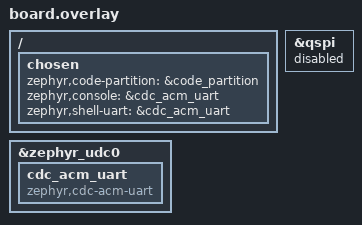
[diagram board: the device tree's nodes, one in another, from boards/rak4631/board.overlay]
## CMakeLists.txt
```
# SPDX-License-Identifier: MIT
# ZephCore Flash Formatter — erases all filesystem partitions, reboots to UF2 DFU.
#
# Build:  west build -b rak4631/nrf52840 zephcore/tools/formatter --pristine
# Flash:  drag-drop build/zephyr/zephyr.uf2 onto UF2 drive

cmake_minimum_required(VERSION 3.20.0)

# Reuse the main project's custom board definitions (overlays for partitions)
list(APPEND BOARD_ROOT ${CMAKE_CURRENT_SOURCE_DIR}/../..)

# Extract base board name (strip qualifier like /nrf52840)
string(REPLACE "/" ";" BOARD_PARTS ${BOARD})
list(GET BOARD_PARTS 0 BOARD_BASE)

# Find board.overlay — prefer formatter-specific overlay (minimal, no sensors/GPS),
# fall back to main board overlay (full hardware definitions).
# Formatter overlays live in tools/formatter/boards/<board>/board.overlay
file(GLOB_RECURSE FMT_OVERLAY_CANDIDATES
     "${CMAKE_CURRENT_SOURCE_DIR}/boards/*/${BOARD_BASE}/board.overlay"
     "${CMAKE_CURRENT_SOURCE_DIR}/boards/${BOARD_BASE}/board.overlay")
if(FMT_OVERLAY_CANDIDATES)
    list(GET FMT_OVERLAY_CANDIDATES 0 FORMATTER_BOARD_OVERLAY)
else()
    # Fall back to main board overlay (partitions + full hardware)
    file(GLOB_RECURSE BOARD_OVERLAY_CANDIDATES
         "${CMAKE_CURRENT_SOURCE_DIR}/../../boards/*/${BOARD_BASE}/board.overlay")
    if(BOARD_OVERLAY_CANDIDATES)
        list(GET BOARD_OVERLAY_CANDIDATES 0 FORMATTER_BOARD_OVERLAY)
    endif()
endif()
if(FORMATTER_BOARD_OVERLAY)
    if(EXTRA_DTC_OVERLAY_FILE)
        set(EXTRA_DTC_OVERLAY_FILE "${EXTRA_DTC_OVERLAY_FILE};${FORMATTER_BOARD_OVERLAY}" CACHE STRING "" FORCE)
    else()
        set(EXTRA_DTC_OVERLAY_FILE "${FORMATTER_BOARD_OVERLAY}" CACHE STRING "" FORCE)
    endif()
endif()

# Find formatter-specific board.conf (e.g., QSPI enablement)
# These live in tools/formatter/boards/<board_base>/board.conf
file(GLOB_RECURSE FMT_BOARD_CONF_CANDIDATES
     "${CMAKE_CURRENT_SOURCE_DIR}/boards/*/${BOARD_BASE}/board.conf"
     "${CMAKE_CURRENT_SOURCE_DIR}/boards/${BOARD_BASE}/board.conf")
if(FMT_BOARD_CONF_CANDIDATES)
    list(GET FMT_BOARD_CONF_CANDIDATES 0 FMT_BOARD_CONF)
    if(EXTRA_CONF_FILE)
        set(EXTRA_CONF_FILE "${EXTRA_CONF_FILE};${FMT_BOARD_CONF}" CACHE STRING "" FORCE)
    else()
        set(EXTRA_CONF_FILE "${FMT_BOARD_CONF}" CACHE STRING "" FORCE)
    endif()
endif()

message(STATUS "Formatter board overlay: ${FORMATTER_BOARD_OVERLAY}")
message(STATUS "Formatter board conf: ${FMT_BOARD_CONF}")

# Read the SoftDevice firmware ID from the MAIN board.conf for this board.
# The Adafruit bootloader rejects a DFU package whose --sd-req doesn't match the
# SoftDevice it's running, which is exactly the guard we want: the SDv6 formatter
# must never apply to an SDv7 node (wrong partition map = corrupted node).
#   SoftDevice v6 -> 0x00B6      SoftDevice v7 -> 0x0123
file(GLOB_RECURSE MAIN_BOARD_CONF_CANDIDATES
     "${CMAKE_CURRENT_SOURCE_DIR}/../../boards/*/${BOARD_BASE}/board.conf")
if(MAIN_BOARD_CONF_CANDIDATES)
    list(GET MAIN_BOARD_CONF_CANDIDATES 0 MAIN_BOARD_CONF)
    file(STRINGS "${MAIN_BOARD_CONF}" _sd_fwid_line REGEX "^CONFIG_ZEPHCORE_SD_FWID=")
    if(_sd_fwid_line)
        string(REGEX REPLACE "^CONFIG_ZEPHCORE_SD_FWID=" "" FORMATTER_SD_REQ "${_sd_fwid_line}")
    endif()
endif()

find_package(Zephyr REQUIRED HINTS $ENV{ZEPHYR_BASE})
project(zephcore_formatter)

target_sources(app PRIVATE src/main.c src/qspi_probe.c)

# Generate an Adafruit DFU package (.zip) next to the .uf2. The .zip is what the
# Mesh America configurator uses for its automated `erase` flow (spec §4a); the
# .uf2 remains the manual drag-and-drop fallback. See PROVIDER_CATALOG.md.
find_program(ADAFRUIT_NRFUTIL adafruit-nrfutil)
if(ADAFRUIT_NRFUTIL AND FORMATTER_SD_REQ)
  add_custom_target(dfu_zip ALL
    COMMAND ${ADAFRUIT_NRFUTIL} dfu genpkg
      --dev-type 0x0052
      --sd-req ${FORMATTER_SD_REQ}
      --application ${CMAKE_BINARY_DIR}/zephyr/zephyr.hex
      ${CMAKE_BINARY_DIR}/zephyr/zephyr.zip
    DEPENDS ${CMAKE_BINARY_DIR}/zephyr/zephyr.hex
    COMMENT "Generating formatter DFU package: zephyr.zip (sd-req=${FORMATTER_SD_REQ})"
    VERBATIM
  )
  add_dependencies(dfu_zip zephyr_final)
  message(STATUS "Formatter DFU zip: ENABLED (sd-req=${FORMATTER_SD_REQ})")
else()
  message(STATUS "Formatter DFU zip: DISABLED (adafruit-nrfutil or SD_FWID missing)")
endif()
```

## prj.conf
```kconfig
# ZephCore Universal Flash Formatter — minimal config
# QSPI erase uses bare-metal register probing (qspi_probe.c) — no driver needed

# Flash access
CONFIG_FLASH=y
CONFIG_FLASH_MAP=y

# Use DTS code_partition for linker origin (required for bootloader boards)
CONFIG_USE_DT_CODE_PARTITION=y

# UF2 output
CONFIG_BUILD_OUTPUT_UF2=y

# USB CDC console (new stack — must match main app)
CONFIG_USB_DEVICE_STACK_NEXT=y
CONFIG_SERIAL=y
CONFIG_CONSOLE=y
CONFIG_UART_CONSOLE=y
CONFIG_UART_LINE_CTRL=y
CONFIG_CDC_ACM_SERIAL_INITIALIZE_AT_BOOT=y
CONFIG_CDC_ACM_SERIAL_ENABLE_AT_BOOT=y

# No logging, no BLE, no LoRa — just erase and reboot
CONFIG_LOG=n
CONFIG_ASSERT=n

# GPIO for LED feedback
CONFIG_GPIO=y

# Reboot API
CONFIG_REBOOT=y

# Don't mount filesystems — we're erasing them
CONFIG_FILE_SYSTEM=n

# Disable peripherals auto-enabled by board overlay DTS nodes.
# Without this, GNSS/I2C/sensor drivers init and hang on boards
# where GPS or sensors aren't physically connected.
CONFIG_GNSS=n
CONFIG_I2C=n
CONFIG_SENSOR=n
CONFIG_SPI=n
```

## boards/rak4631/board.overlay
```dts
/*
 * RAK4631 formatter overlay — flash partitions + USB console only.
 * Strips all sensor/GPS/radio nodes from the main board overlay
 * to avoid driver init hangs in the minimal formatter environment.
 */

/delete-node/ &boot_partition;
/delete-node/ &slot0_partition;
/delete-node/ &slot1_partition;
/delete-node/ &storage_partition;

/ {
	chosen {
		zephyr,code-partition = &code_partition;
		zephyr,console = &cdc_acm_uart;
		zephyr,shell-uart = &cdc_acm_uart;
		/* No zephyr,settings-partition — nRF52 uses file-based settings */
	};
};

&zephyr_udc0 {
	cdc_acm_uart: cdc_acm_uart {
		compatible = "zephyr,cdc-acm-uart";
	};
};

/* Disable QSPI — RAK19003 Mini Base has no QSPI flash */
&qspi {
	status = "disabled";
};

/* Arduino MeshCore compatible partition layout (SoftDevice v6) */
#include "../../../../boards/common/nrf52_partitions_sdv6.dtsi"
```

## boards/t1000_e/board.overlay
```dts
/*
 * T1000-E formatter overlay — USB console only.
 * Strips GPS/sensor nodes from the main board overlay
 * to avoid driver init hangs in the minimal formatter environment.
 *
 * This overlay is used as the SDv7 universal build target.
 * The resulting UF2 works on ALL nRF52840 boards with SoftDevice v7:
 *   T1000-E, Wio Tracker L1, Ikoka Nano 30dBm
 */

/ {
	chosen {
		zephyr,console = &cdc_acm_uart;
		zephyr,shell-uart = &cdc_acm_uart;
	};

	/* Delete GPS control nodes from main board overlay */
	/delete-node/ gps-enable;
	/delete-node/ gps-vrtc-enable;
	/delete-node/ gps-reset;
	/delete-node/ gps-sleep-int;
	/delete-node/ gps-rtc-int;
	/delete-node/ gps-resetb;
};

&zephyr_udc0 {
	cdc_acm_uart: cdc_acm_uart {
		compatible = "zephyr,cdc-acm-uart";
	};
};
```

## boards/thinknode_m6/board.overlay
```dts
/*
 * ThinkNode M6 formatter overlay — minimal drivers.
 *
 * The M6 board DTS no longer carries the QSPI flash: no shipped unit has the
 * chip fitted, so the board dropped &qspi, its partition, the P0.21 enable
 * regulator and the qspi-ext.dtsi (/ext) include together (see the note in
 * thinknode_m6.dts).  There is therefore no /ext LittleFS instance to drop
 * and no QSPI enable to hog here; main.c's PARTITION_EXISTS() checks
 * simply skip the QSPI erase.  If the board ever restores QSPI, restore the
 * "/delete-node/ &qspi_lfs;" and the P0.21 hog that used to live here.
 *
 * Replace the regulator-fixed power-enable node with a gpio-hog so
 * CONFIG_REGULATOR is not forced on by regulator-boot-on.
 */

/* Remove regulator-fixed node and replace with a gpio-hog */
/delete-node/ &pwr_enable;

&gpio0 {
	/* Board power enable (PIN_PWR_EN = P0.27) */
	pwr-en-hog {
		gpio-hog;
		gpios = <27 GPIO_ACTIVE_HIGH>;
		output-high;
		line-name = "PWR Enable";
	};
};
```

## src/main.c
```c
/*
 * ZephCore Universal Flash Formatter
 *
 * Erases all filesystem partitions and reboots into Adafruit UF2 DFU mode
 * for clean firmware installation.
 *
 * Only TWO UF2 binaries are needed for all nRF52840 boards:
 *   - SDv6: covers RAK4631, ThinkNode M1/M3/M6, ProMicro LR2021, RAK WisMesh Tag
 *   - SDv7: covers T1000-E, Wio Tracker L1, Ikoka Nano 30dBm
 *
 * Internal flash uses DTS PARTITION_EXISTS — partition layout is identical
 * across all boards with the same SoftDevice version.
 *
 * QSPI external flash uses bare-metal register probing (qspi_probe.c) — no
 * Zephyr QSPI driver needed. The probe table contains known pin configurations
 * for all QSPI-capable boards; it auto-detects which board is running and
 * erases the external flash if present, or silently skips if not.
 *
 * Build:
 *   SDv6:  west build -b rak4631/nrf52840  zephcore/tools/formatter --pristine
 *   SDv7:  west build -b t1000_e/nrf52840  zephcore/tools/formatter --pristine
 *
 * Flash: drag-drop build/zephyr/zephyr.uf2 onto UF2 drive
 *
 * SPDX-License-Identifier: MIT
 */

#include <zephyr/kernel.h>
#include <zephyr/device.h>
#include <zephyr/drivers/flash.h>
#include <zephyr/drivers/gpio.h>
#include <zephyr/storage/flash_map.h>
#include <zephyr/sys/reboot.h>
#include <errno.h>
#include "qspi_probe.h"

#if defined(CONFIG_SOC_SERIES_NRF52)
#include <hal/nrf_power.h>
#define IS_NRF52 1
#else
#define IS_NRF52 0
#endif

/* Adafruit UF2 bootloader magic — enter mass storage DFU mode */
#define BOOTLOADER_DFU_UF2_MAGIC  0x57

/* ── LED feedback (optional — may not match actual board) ──── */

#if DT_NODE_EXISTS(DT_ALIAS(led0)) && !IS_NRF52
/* Only use DTS LED on non-nRF52 (board-specific builds).
 * On nRF52 universal builds, skip LED to avoid toggling
 * wrong pins on boards other than the build target. */
#define HAS_LED 1
static const struct gpio_dt_spec led = GPIO_DT_SPEC_GET(DT_ALIAS(led0), gpios);
static void led_init(void)  { gpio_pin_configure_dt(&led, GPIO_OUTPUT_ACTIVE); }
static void led_on(void)    { gpio_pin_set_dt(&led, 1); }
static void led_off(void)   { gpio_pin_set_dt(&led, 0); }
#else
#define HAS_LED 0
static void led_init(void)  {}
static void led_on(void)    {}
static void led_off(void)   {}
#endif

/* ── Flash erase helper ──────────────────────────────────────── */

static int erase_partition(uint8_t id, const char *name)
{
	const struct flash_area *fa;
	int rc;

	rc = flash_area_open(id, &fa);
	if (rc) {
		printk("  %s: open failed (rc %d) — skipped\n", name, rc);
		return rc;
	}

	printk("  %s: erasing 0x%lx - 0x%lx (%u KB)...",
	       name,
	       (unsigned long)fa->fa_off,
	       (unsigned long)(fa->fa_off + fa->fa_size),
	       (unsigned)(fa->fa_size / 1024));

	rc = flash_area_erase(fa, 0, fa->fa_size);
	if (rc) {
		printk(" FAILED (rc %d)\n", rc);
	} else {
		printk(" OK\n");
	}

	flash_area_close(fa);
	return rc;
}

/* ── Main ────────────────────────────────────────────────────── */

int main(void)
{
	int errors = 0;

	/* Brief delay for USB CDC to enumerate */
	k_msleep(2000);

	printk("\n");
	printk("=== ZephCore Flash Formatter ===\n");
	printk("\n");

	led_init();
	led_on();

	/* ── LittleFS partition (all platforms) ── */
#if PARTITION_EXISTS(lfs_partition)
	if (erase_partition(PARTITION_ID(lfs_partition), "LittleFS (/lfs)")) {
		errors++;
	}
#endif

	/* ── NVS storage partition (ESP32 etc.) ── */
#if PARTITION_EXISTS(storage_partition)
	if (erase_partition(PARTITION_ID(storage_partition), "NVS (storage)")) {
		errors++;
	}
#endif

	/* ── QSPI external flash (auto-detect via pin probing) ── */
	/* Probes all known boards. Finding no flash is normal (most boards have
	 * none); a flash that answered and then failed to erase is an error. */
	int qspi_rc = qspi_probe_and_erase();

	if (qspi_rc && qspi_rc != -ENODEV) {
		errors++;
	}

	led_off();

	/* ── Summary ── */
	printk("\n");
	if (errors) {
		printk("Completed with %d error(s).\n", errors);
	} else if (qspi_rc == 0) {
		printk("All partitions erased successfully (internal flash + QSPI).\n");
	} else {
		printk("Internal flash erased successfully. No external QSPI flash was\n");
		printk("erased: none answered (normal on a board without one).\n");
	}

	printk("Rebooting into UF2 DFU mode...\n");
	printk("You can now drag-drop your new firmware UF2.\n");
	k_msleep(500);

	/* ── Reboot to UF2 bootloader ── */
#if IS_NRF52
	nrf_power_gpregret_set(NRF_POWER, 0, BOOTLOADER_DFU_UF2_MAGIC);
#endif
	sys_reboot(SYS_REBOOT_COLD);

	return 0; /* never reached */
}
```

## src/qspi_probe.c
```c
/*
 * SPDX-License-Identifier: MIT
 * Universal QSPI flash probe and erase — bare-metal nRF52840 register access
 *
 * Bypasses the Zephyr QSPI driver entirely. Directly configures the nRF52840
 * QSPI peripheral's PSEL (pin select) registers, sends standard JEDEC SPI NOR
 * commands via the custom instruction interface (CINSTR), and performs a full
 * chip erase when a flash chip responds.
 *
 * To add a new board: append an entry to known_boards[] with its QSPI pin
 * mapping and optional power-enable GPIO. No DTS or Kconfig changes needed.
 */

#include <zephyr/kernel.h>
#include <zephyr/devicetree.h>
#include <errno.h>
#include "qspi_probe.h"

#if defined(CONFIG_SOC_NRF52840)

#include <nrfx.h>
#include <hal/nrf_gpio.h>

/* ── SPI NOR flash commands (JEDEC standard — all chips) ──── */

#define CMD_READ_ID      0x9F  /* Read JEDEC ID: manufacturer + type + capacity */
#define CMD_WRITE_EN     0x06  /* Write Enable (required before erase) */
#define CMD_CHIP_ERASE   0xC7  /* Full chip erase */
#define CMD_READ_STATUS  0x05  /* Read Status Register 1 */
#define CMD_RELEASE_DPD  0xAB  /* Release from Deep Power-Down */
#define CMD_READ         0x03  /* Read data, 24-bit address */
#define STATUS_WIP       0x01  /* Write-In-Progress bit in status register */

/* ── CINSTRCONF length values (opcode + N-1 data bytes) ───── */

#define CINSTR_1B   1  /* opcode only */
#define CINSTR_2B   2  /* opcode + 1 byte response */
#define CINSTR_4B   4  /* opcode + 3 bytes response (JEDEC ID) */
#define CINSTR_8B   8  /* opcode + 3 address bytes + 4 data bytes (READ) */

/* A flash behind a switched rail needs time after the rail comes up before it
 * answers: one settle, then a few more tries (MeshTracker X1 answered 00 00 00
 * right after its rail was switched on). */
#define PWR_SETTLE_MS    100
#define PWR_RETRY_MS     200
#define PWR_RETRIES      2

/* Which SoftDevice this image is built for, from where the application starts
 * (0x26000 under v6, 0x27000 under v7). */
#define SD_ANY  0
#define SD_V6   6
#define SD_V7   7
#define BUILD_SD ((DT_REG_ADDR(DT_CHOSEN(zephyr_code_partition)) == 0x27000) ? SD_V7 : SD_V6)

/* ── Pin encoding: matches nRF52840 PSEL register format ──── */

#define QPIN(port, pin)    (((port) << 5) | (pin))
#define QPIN_NONE          0xFF
#define QPIN_PORT(p)       (((p) >> 5) & 1)
#define QPIN_PIN(p)        ((p) & 0x1F)

/* PSEL register value: pin connected */
#define PSEL_DISCONNECT    (1UL << 31)

/* ── Known board QSPI pin configurations ─────────────────── */

struct qspi_pin_config {
	const char *name;
	uint8_t sck, csn, io0, io1, io2, io3;
	uint8_t pwr_pin;  /* GPIO to drive HIGH before probe, QPIN_NONE if none */
	uint8_t sd;       /* SD_V6/SD_V7: probe only in that build; SD_ANY: both */
};

/*
 * Pin table — add new boards here.
 * Sourced from ZephCore DTS + Arduino MeshCore variants.
 *
 * PWR is the GPIO that switches the flash's supply rail. The firmware raises it
 * from a regulator node; here nothing else does, and the rail has been off for
 * the bootloader's whole DFU, so a missing PWR pin reads as "no flash".
 *
 * Config                     SCK      CSN      IO0      IO1      IO2      IO3      PWR      Flash chip       Boards
 * ───────────────────────── ──────── ──────── ──────── ──────── ──────── ──────── ──────── ──────────────── ────────────────────────────────────────
 * Wio/XIAO/Ikoka/SenseCap   P0.21    P0.25    P0.20    P0.24    P0.22    P0.23    —        P25Q16H 2MB      Wio Tracker L1 (+ Pro 1W), XIAO nRF52, Ikoka Stick/Nano/Handheld, SenseCap Solar
 * ThinkNode M1 / TEcho       P1.14    P1.15    P1.12    P1.13    P0.07    P0.05    P0.12    MX25R1635F 2MB   ThinkNode M1, LilyGo TEcho
 * ThinkNode M6               P1.03    P0.23    P1.01    P1.02    P1.04    P1.05    P0.21    MX25R1635F 2MB   ThinkNode M6
 * RAK4631 / GAT562           P0.03    P0.26    P0.30    P0.29    P0.28    P0.02    —        IS25LP080D 1MB   RAK4631, RAK3401, GAT562 variants
 * LilyGo TEcho Lite          P0.04    P0.12    P0.06    P0.08    P1.09    P0.26    —        ZD25WQ32C 4MB    LilyGo TEcho Lite
 * Nano G2 Ultra              P0.08    P1.07    P0.06    P0.26    P1.04    P1.02    —        W25Q16JV 2MB     Nano G2 Ultra
 * LilyGo T-Impulse Plus      P0.04    P0.12    P0.06    P1.09    P0.08    P0.26    P0.14    ZD25WQ32C 4MB    LilyGo T-Impulse Plus (SD v6; IO1/IO2 are the TEcho Lite's swapped)
 * MeshTracker X1             P0.19    P0.20    P0.21    P0.22    P0.23    P1.00    P0.15    GD25Q64E 8MB     MeshTracker X1 (SD v7)
 */
static const struct qspi_pin_config known_boards[] = {
	{
		.name = "Wio/XIAO/Ikoka/SenseCap",
		.sck = QPIN(0, 21), .csn = QPIN(0, 25),
		.io0 = QPIN(0, 20), .io1 = QPIN(0, 24),
		.io2 = QPIN(0, 22), .io3 = QPIN(0, 23),
		.pwr_pin = QPIN_NONE,
	},
	{
		.name = "ThinkNode M1 / TEcho",
		.sck = QPIN(1, 14), .csn = QPIN(1, 15),
		.io0 = QPIN(1, 12), .io1 = QPIN(1, 13),
		.io2 = QPIN(0,  7), .io3 = QPIN(0,  5),
		.pwr_pin = QPIN(0, 12),
	},
	{
		.name = "ThinkNode M6",
		.sck = QPIN(1,  3), .csn = QPIN(0, 23),
		.io0 = QPIN(1,  1), .io1 = QPIN(1,  2),
		.io2 = QPIN(1,  4), .io3 = QPIN(1,  5),
		.pwr_pin = QPIN(0, 21),
	},
	{
		.name = "RAK4631 / GAT562",
		.sck = QPIN(0,  3), .csn = QPIN(0, 26),
		.io0 = QPIN(0, 30), .io1 = QPIN(0, 29),
		.io2 = QPIN(0, 28), .io3 = QPIN(0,  2),
		.pwr_pin = QPIN_NONE,
	},
	{
		.name = "LilyGo TEcho Lite",
		.sck = QPIN(0,  4), .csn = QPIN(0, 12),
		.io0 = QPIN(0,  6), .io1 = QPIN(0,  8),
		.io2 = QPIN(1,  9), .io3 = QPIN(0, 26),
		.pwr_pin = QPIN_NONE,
	},
	{
		.name = "Nano G2 Ultra",
		.sck = QPIN(0,  8), .csn = QPIN(1,  7),
		.io0 = QPIN(0,  6), .io1 = QPIN(0, 26),
		.io2 = QPIN(1,  4), .io3 = QPIN(1,  2),
		.pwr_pin = QPIN_NONE,
	},
	{
		.name = "LilyGo T-Impulse Plus",
		.sck = QPIN(0,  4), .csn = QPIN(0, 12),
		.io0 = QPIN(0,  6), .io1 = QPIN(1,  9),
		.io2 = QPIN(0,  8), .io3 = QPIN(0, 26),
		.pwr_pin = QPIN(0, 14),
		.sd = SD_V6,
	},
	{
		.name = "MeshTracker X1",
		.sck = QPIN(0, 19), .csn = QPIN(0, 20),
		.io0 = QPIN(0, 21), .io1 = QPIN(0, 22),
		.io2 = QPIN(0, 23), .io3 = QPIN(1,  0),
		.pwr_pin = QPIN(0, 15),
		.sd = SD_V7,
	},
};

/* ── GPIO helpers (raw register access) ───────────────────── */

static NRF_GPIO_Type *gpio_port_reg(uint8_t qpin)
{
	return QPIN_PORT(qpin) ? NRF_P1 : NRF_P0;
}

static void gpio_set_output_high(uint8_t qpin)
{
	NRF_GPIO_Type *port = gpio_port_reg(qpin);
	uint8_t pin = QPIN_PIN(qpin);

	nrf_gpio_cfg_output(qpin);
	port->OUTSET = (1UL << pin);
}

static void gpio_release(uint8_t qpin)
{
	NRF_GPIO_Type *port = gpio_port_reg(qpin);
	uint8_t pin = QPIN_PIN(qpin);

	port->OUTCLR = (1UL << pin);
	nrf_gpio_cfg_default(qpin);
}

/* ── QSPI register helpers ────────────────────────────────── */

static void qspi_disconnect_pins(void)
{
	NRF_QSPI->PSEL.SCK = PSEL_DISCONNECT;
	NRF_QSPI->PSEL.CSN = PSEL_DISCONNECT;
	NRF_QSPI->PSEL.IO0 = PSEL_DISCONNECT;
	NRF_QSPI->PSEL.IO1 = PSEL_DISCONNECT;
	NRF_QSPI->PSEL.IO2 = PSEL_DISCONNECT;
	NRF_QSPI->PSEL.IO3 = PSEL_DISCONNECT;
}

static void qspi_set_pins(const struct qspi_pin_config *cfg)
{
	NRF_QSPI->PSEL.SCK = cfg->sck;
	NRF_QSPI->PSEL.CSN = cfg->csn;
	NRF_QSPI->PSEL.IO0 = cfg->io0;
	NRF_QSPI->PSEL.IO1 = cfg->io1;
	NRF_QSPI->PSEL.IO2 = cfg->io2;
	NRF_QSPI->PSEL.IO3 = cfg->io3;
}

static bool qspi_wait_ready(int timeout_ms)
{
	int64_t deadline = k_uptime_get() + timeout_ms;

	while (!NRF_QSPI->EVENTS_READY) {
		if (k_uptime_get() > deadline) {
			return false;
		}
		k_msleep(1);
	}
	NRF_QSPI->EVENTS_READY = 0;
	return true;
}

static bool qspi_activate(void)
{
	/* Single-bit SPI mode, 24-bit addressing, no DPM */
	NRF_QSPI->IFCONFIG0 = 0;

	/* 2 MHz (SCKFREQ=15 → 32MHz/16), 8µs CSN delay, SPI mode 0 */
	NRF_QSPI->IFCONFIG1 = (15UL << 28) | 128;

	NRF_QSPI->ENABLE = QSPI_ENABLE_ENABLE_Enabled;
	NRF_QSPI->EVENTS_READY = 0;
	NRF_QSPI->TASKS_ACTIVATE = 1;

	return qspi_wait_ready(500);
}

static void qspi_deactivate(void)
{
	NRF_QSPI->EVENTS_READY = 0;
	NRF_QSPI->TASKS_DEACTIVATE = 1;
	qspi_wait_ready(500);
	NRF_QSPI->ENABLE = QSPI_ENABLE_ENABLE_Disabled;
	qspi_disconnect_pins();
}

/**
 * Execute a custom instruction via CINSTR interface.
 * @param opcode  SPI NOR command opcode
 * @param len     Total bytes (opcode + response), 1-9
 * @param dat0    Output: CINSTRDAT0 register value (response bytes), or NULL
 * @return true on success, false on timeout
 */
static bool qspi_cinstr(uint8_t opcode, uint8_t len, uint32_t *dat0)
{
	NRF_QSPI->CINSTRDAT0 = 0;
	NRF_QSPI->EVENTS_READY = 0;
	NRF_QSPI->CINSTRCONF = ((uint32_t)opcode) |
				((uint32_t)len << 8) |
				(1UL << 12) |  /* LIO2: hold IO2 HIGH (not used in single-bit) */
				(1UL << 13);   /* LIO3: hold IO3 HIGH (not used in single-bit) */

	if (!qspi_wait_ready(500)) {
		return false;
	}

	if (dat0) {
		*dat0 = NRF_QSPI->CINSTRDAT0;
	}
	return true;
}

/**
 * Read the 4 bytes at flash address 0 (READ 0x03, single-line).
 * The address goes out from CINSTRDAT0 bytes 0-2; the data comes back in the
 * byte slots after it: CINSTRDAT0 byte 3 and CINSTRDAT1 bytes 0-2.
 */
static bool qspi_read_first4(uint32_t *out)
{
	NRF_QSPI->CINSTRDAT0 = 0;
	NRF_QSPI->CINSTRDAT1 = 0;
	NRF_QSPI->EVENTS_READY = 0;
	NRF_QSPI->CINSTRCONF = ((uint32_t)CMD_READ) |
				((uint32_t)CINSTR_8B << 8) |
				(1UL << 12) | (1UL << 13);

	if (!qspi_wait_ready(500)) {
		return false;
	}

	*out = (NRF_QSPI->CINSTRDAT0 >> 24) | (NRF_QSPI->CINSTRDAT1 << 8);
	return true;
}

/* ── Per-config probe and erase ───────────────────────────── */

/* @return 0 erased, -ENODEV nothing answered on these pins, -EIO a flash
 * answered but the erase failed.
 */
static int probe_one(const struct qspi_pin_config *cfg)
{
	uint32_t dat0, first4;
	uint8_t mfr, type, cap;
	int rc = -ENODEV;

	printk("  Probing %s pins...", cfg->name);

	/* Power-enable GPIO if needed */
	if (cfg->pwr_pin != QPIN_NONE) {
		gpio_set_output_high(cfg->pwr_pin);
		k_msleep(PWR_SETTLE_MS);
	}

	/* Activate with the pins disconnected, connect them afterwards (what
	 * Zephyr's nrf_qspi_nor exit_dpd() does). ACTIVATE polls the flash's
	 * status register until WIP reads 0; a part in deep power-down, or no
	 * part at all, leaves IO1 floating and READY may never come.
	 */
	NRF_QSPI->ENABLE = QSPI_ENABLE_ENABLE_Disabled;
	qspi_disconnect_pins();

	if (!qspi_activate()) {
		printk(" activate timeout\n");
		goto fail;
	}
	qspi_set_pins(cfg);

	for (int attempt = 0; ; attempt++) {
		/* A repeater, room server or observer leaves the flash in deep
		 * power-down, and the reset into this formatter does not wake
		 * it: it then ignores everything but this command.
		 */
		if (!qspi_cinstr(CMD_RELEASE_DPD, CINSTR_1B, NULL)) {
			printk(" wake timeout\n");
			goto fail_deactivate;
		}
		k_msleep(1);

		/* READ JEDEC ID (0x9F → 3 bytes: manufacturer, type, capacity) */
		if (!qspi_cinstr(CMD_READ_ID, CINSTR_4B, &dat0)) {
			printk(" read ID timeout\n");
			goto fail_deactivate;
		}

		mfr  = (dat0 >>  0) & 0xFF;
		type = (dat0 >>  8) & 0xFF;
		cap  = (dat0 >> 16) & 0xFF;

		/* Validate — reject bus-float (0xFF) and bus-ground (0x00) */
		if (mfr != 0xFF && mfr != 0x00) {
			break;
		}
		if (cfg->pwr_pin == QPIN_NONE || attempt >= PWR_RETRIES) {
			printk(" no flash (ID=%02X %02X %02X)\n", mfr, type, cap);
			goto fail_deactivate;
		}
		k_msleep(PWR_RETRY_MS);
	}

	printk(" found! JEDEC=%02X %02X %02X (%u KB)\n",
	       mfr, type, cap, (unsigned)((1UL << cap) / 1024));

	/* From here on a failure is an error, not "no flash". */
	rc = -EIO;

	if (qspi_read_first4(&first4)) {
		printk("  First bytes before: %08X\n", (unsigned)first4);
	}

	/* ── Erase ── */
	printk("  Erasing QSPI flash...");

	/* WRITE ENABLE */
	if (!qspi_cinstr(CMD_WRITE_EN, CINSTR_1B, NULL)) {
		printk(" WREN failed\n");
		goto fail_deactivate;
	}

	/* CHIP ERASE */
	if (!qspi_cinstr(CMD_CHIP_ERASE, CINSTR_1B, NULL)) {
		printk(" erase cmd failed\n");
		goto fail_deactivate;
	}

	/* Poll status register until WIP clears (chip erase: up to 60s typical) */
	int elapsed_ms = 0;
	const int poll_interval_ms = 500;
	const int timeout_ms = 120000;

	while (elapsed_ms < timeout_ms) {
		k_msleep(poll_interval_ms);
		elapsed_ms += poll_interval_ms;

		if (!qspi_cinstr(CMD_READ_STATUS, CINSTR_2B, &dat0)) {
			printk(" status poll failed\n");
			goto fail_deactivate;
		}

		if (!(dat0 & STATUS_WIP)) {
			/* A chip erase the part refused (write-protected)
			 * also ends with WIP clear: check it took.
			 */
			if (!qspi_read_first4(&first4) || first4 != 0xFFFFFFFF) {
				printk(" FAILED (first bytes after: %08X)\n",
				       (unsigned)first4);
				goto fail_deactivate;
			}
			printk(" OK (%d.%ds)\n",
			       elapsed_ms / 1000,
			       (elapsed_ms % 1000) / 100);
			qspi_deactivate();
			if (cfg->pwr_pin != QPIN_NONE) {
				gpio_release(cfg->pwr_pin);
			}
			return 0;
		}
	}

	printk(" TIMEOUT (>120s)\n");

fail_deactivate:
	qspi_deactivate();
fail:
	if (cfg->pwr_pin != QPIN_NONE) {
		gpio_release(cfg->pwr_pin);
	}
	return rc;
}

/* ── Public API ───────────────────────────────────────────── */

int qspi_probe_and_erase(void)
{
	printk("  QSPI: probing known pin configurations...\n");

	for (int i = 0; i < (int)ARRAY_SIZE(known_boards); i++) {
		int rc;

		if (known_boards[i].sd != SD_ANY && known_boards[i].sd != BUILD_SD) {
			continue;
		}

		rc = probe_one(&known_boards[i]);
		if (rc != -ENODEV) {
			return rc;
		}
	}

	printk("  QSPI: no external flash found — skipped\n");
	return -ENODEV;
}

#else /* !CONFIG_SOC_NRF52840 */

int qspi_probe_and_erase(void)
{
	printk("  QSPI: not supported on this platform\n");
	return -ENODEV;
}

#endif /* CONFIG_SOC_NRF52840 */
```

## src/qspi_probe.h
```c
/*
 * SPDX-License-Identifier: MIT
 * Universal QSPI flash probe and erase — bare-metal nRF52840 QSPI register access
 *
 * Probes all known pin configurations to detect external QSPI flash,
 * then performs a full chip erase if found. No Zephyr QSPI driver needed.
 */

#ifndef QSPI_PROBE_H
#define QSPI_PROBE_H

/**
 * Probe all known QSPI pin configurations for connected flash.
 * If found, erase the entire chip.
 *
 * @return 0 if a chip was found and erased, -ENODEV if no chip answered (or the
 *         platform has no QSPI), -EIO if a chip answered but the erase failed
 */
int qspi_probe_and_erase(void);

#endif /* QSPI_PROBE_H */
```
